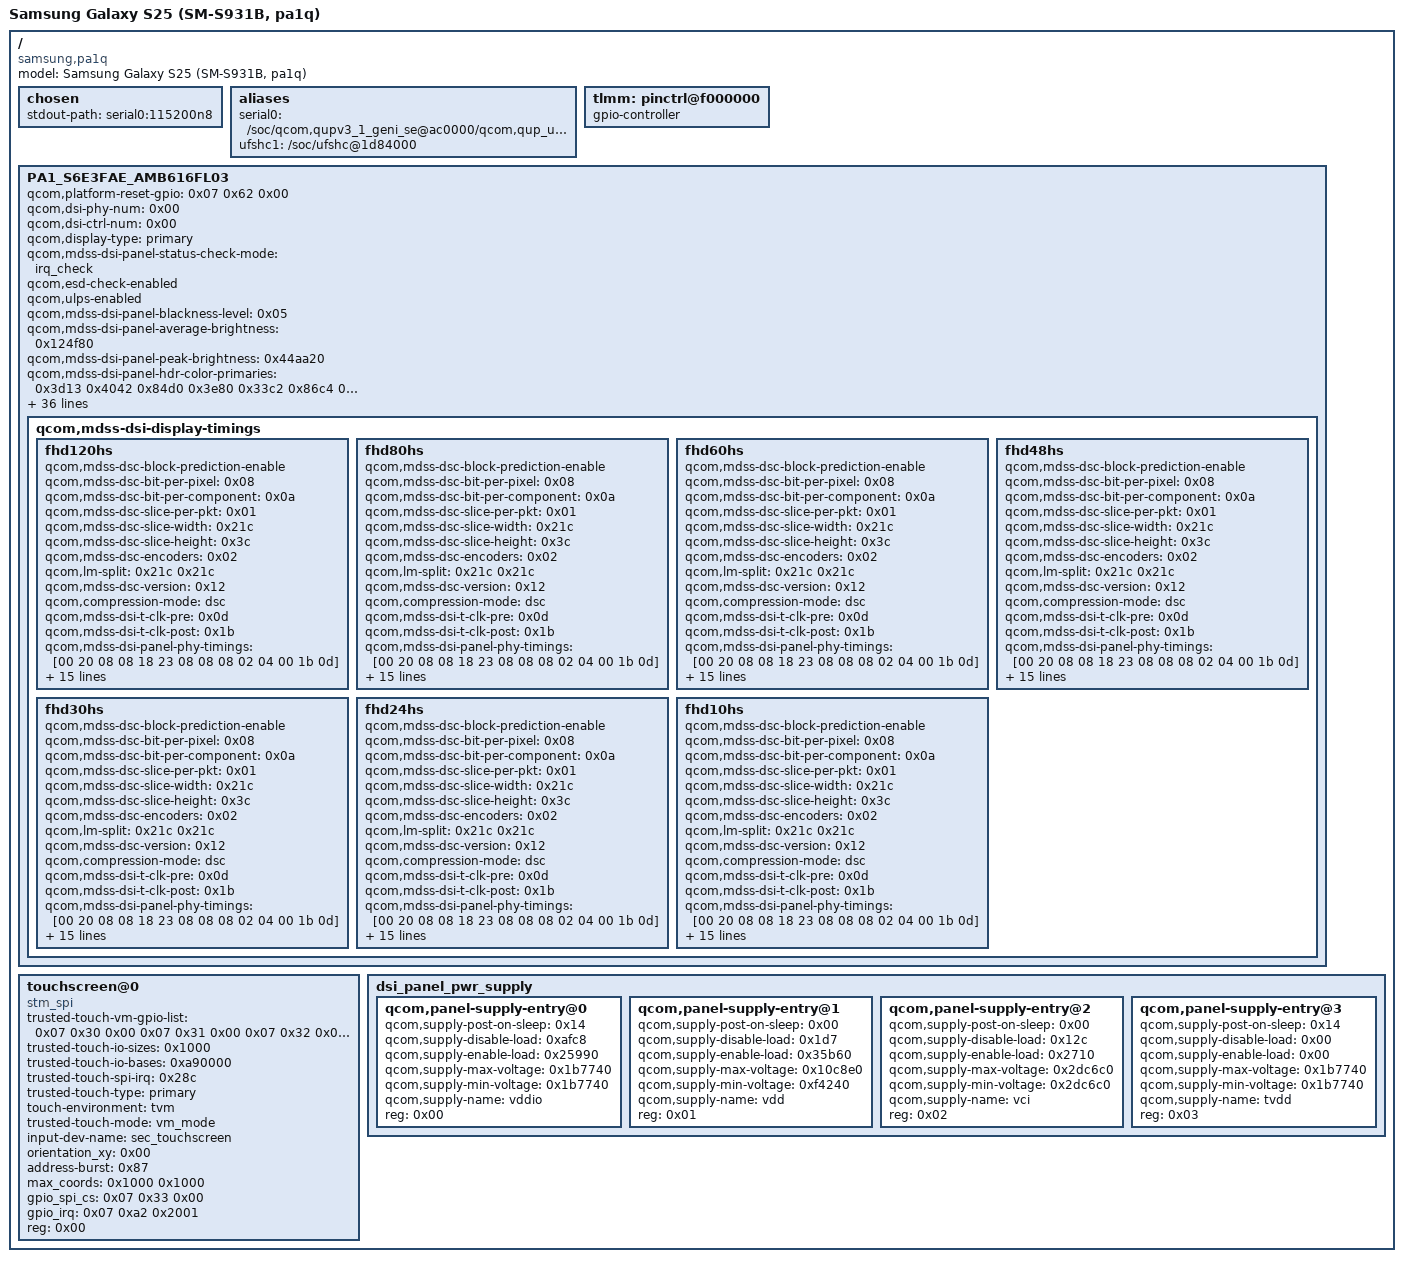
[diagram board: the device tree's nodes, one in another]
/dts-v1/;

/*
 * pa1q (Galaxy S25, SM-S931B) board overlay: the nodes the Sun base tree does not carry.
 *
 * Every value here was extracted from the phone's own firmware, not from the port record:
 * the Sun DTB that ships inside `partitions/vm-bootsys_a` (the graphics VM's tree, which
 * carries the panel, touch and rail nodes for this board). The base SoC tree is `dtb_9`
 * ("Sun SoC", qcom,msn-id 0x26a) of the vendor_boot DTB section. Provenance and the
 * extraction command are in README.md; `check.sh` re-reads the numbers and fails if this
 * file and the firmware disagree.
 *
 * The panel is a Samsung S6E3FAE AMOLED, AMB616FL03, 1080x2340, DSI command mode with DSC,
 * seven refresh rates (120/80/60/48/30/24/10 Hz). Touch is an STMicroelectronics controller
 * on QUPv3 SE4 (spi@a90000). The panel rails are vddio 1.8 V, vdd 1.0-1.1 V, vci 3.0 V,
 * tvdd 1.8 V.
 */

/ {
	model = "Samsung Galaxy S25 (SM-S931B, pa1q)";
	compatible = "samsung,pa1q", "qcom,sun";

	chosen {
		stdout-path = "serial0:115200n8";
	};

	aliases {
		serial0 = "/soc/qcom,qupv3_1_geni_se@ac0000/qcom,qup_uart@a9c000";
		ufshc1 = "/soc/ufshc@1d84000";
	};

	/* Placeholder for the TLMM the extracted nodes point at by phandle. The real node is
	 * pinctrl@f000000 in the Sun base tree. */
	tlmm: pinctrl@f000000 {
		phandle = <0x07>;
		#gpio-cells = <0x02>;
		gpio-controller;
	};

	/* ---------------------------------------------------------------- panel */

			PA1_S6E3FAE_AMB616FL03: PA1_S6E3FAE_AMB616FL03 {
				phandle = <0x53>;
				qcom,platform-reset-gpio = <0x07 0x62 0x00>;
				qcom,dsi-phy-num = <0x00>;
				qcom,dsi-ctrl-num = <0x00>;
				qcom,display-type = "primary";
				qcom,mdss-dsi-panel-status-check-mode = "irq_check";
				qcom,esd-check-enabled;
				qcom,ulps-enabled;
				qcom,mdss-dsi-panel-blackness-level = <0x05>;
				qcom,mdss-dsi-panel-average-brightness = <0x124f80>;
				qcom,mdss-dsi-panel-peak-brightness = <0x44aa20>;
				qcom,mdss-dsi-panel-hdr-color-primaries = <0x3d13 0x4042 0x84d0 0x3e80 0x33c2 0x86c4 0x1d4c 0xbb8>;
				qcom,mdss-dsi-panel-hdr-enabled;
				qcom,mdss-dsi-tx-eot-append;
				qcom,mdss-dsi-rx-eot-ignore;
				qcom,mdss-dsi-panel-mode-gpio-state = "invalid";
				qcom,mdss-pan-physical-height-dimension = <0x8e>;
				qcom,mdss-pan-physical-width-dimension = <0x42>;
				qcom,mdss-dsi-dma-trigger = "trigger_sw";
				qcom,mdss-dsi-mdp-trigger = "none";
				qcom,mdss-dsi-t-clk-pre = <0x19>;
				qcom,mdss-dsi-t-clk-post = <0x18>;
				qcom,mdss-dsi-lane-3-state;
				qcom,mdss-dsi-lane-2-state;
				qcom,mdss-dsi-lane-1-state;
				qcom,mdss-dsi-lane-0-state;
				qcom,mdss-dsi-color-order = "rgb_swap_rgb";
				qcom,mdss-dsi-virtual-channel-id = <0x00>;
				qcom,mdss-dsi-pixel-packing = "loose";
				qcom,mdss-dsi-wr-mem-continue = <0x3c>;
				qcom,mdss-dsi-wr-mem-start = <0x2c>;
				qcom,mdss-dsi-te-dcs-command = <0x01>;
				qcom,dynamic-mode-switch-type = "dynamic-resolution-switch-immediate";
				qcom,dynamic-mode-switch-enabled;
				qcom,mdss-dsi-te-pin-select = <0x01>;
				qcom,mdss-dsi-panel-type = "dsi_cmd_mode";
				qcom,mdss-dsi-interleave-mode = <0x00>;
				qcom,mdss-brightness-default-level = <0x9f6>;
				qcom,mdss-dsi-bl-min-level = <0x01>;
				qcom,mdss-dsi-bl-pmic-control-type = "bl_ctrl_dcs";
				qcom,mdss-dsi-border-color = <0x00>;
				qcom,mdss-dsi-underflow-color = <0xff>;
				qcom,mdss-dsi-bpp = <0x1e>;
				label = "PA1_S6E3FAE_AMB616FL03";
				qcom,mdss-dsi-panel-name = "PA1_S6E3FAE_AMB616FL03";

				qcom,mdss-dsi-display-timings {

					fhd120hs {
						qcom,mdss-dsc-block-prediction-enable;
						qcom,mdss-dsc-bit-per-pixel = <0x08>;
						qcom,mdss-dsc-bit-per-component = <0x0a>;
						qcom,mdss-dsc-slice-per-pkt = <0x01>;
						qcom,mdss-dsc-slice-width = <0x21c>;
						qcom,mdss-dsc-slice-height = <0x3c>;
						qcom,mdss-dsc-encoders = <0x02>;
						qcom,lm-split = <0x21c 0x21c>;
						qcom,mdss-dsc-version = <0x12>;
						qcom,compression-mode = "dsc";
						qcom,mdss-dsi-t-clk-pre = <0x0d>;
						qcom,mdss-dsi-t-clk-post = <0x1b>;
						qcom,mdss-dsi-panel-phy-timings = [00 20 08 08 18 23 08 08 08 02 04 00 1b 0d];
						qcom,mdss-dsi-panel-clockrate = <0x38af1bc0>;
						qcom,mdss-mdp-transfer-time-us = <0x1d6d>;
						qcom,mdss-dsi-panel-framerate = <0x78>;
						samsung,mdss-dsi-sot-hs-mode;
						qcom,mdss-dsi-v-front-porch = <0x0c>;
						qcom,mdss-dsi-v-back-porch = <0x1c>;
						qcom,mdss-dsi-v-pulse-width = <0x1c>;
						qcom,mdss-dsi-h-sync-skew = <0x00>;
						qcom,mdss-dsi-h-front-porch = <0x1c>;
						qcom,mdss-dsi-h-back-porch = <0x1c>;
						qcom,mdss-dsi-h-pulse-width = <0x1c>;
						qcom,mdss-dsi-panel-height = <0x924>;
						qcom,mdss-dsi-panel-width = <0x438>;
						qcom,default-topology-index = <0x00>;
						qcom,display-topology = <0x02 0x02 0x01>;
					};

					fhd80hs {
						qcom,mdss-dsc-block-prediction-enable;
						qcom,mdss-dsc-bit-per-pixel = <0x08>;
						qcom,mdss-dsc-bit-per-component = <0x0a>;
						qcom,mdss-dsc-slice-per-pkt = <0x01>;
						qcom,mdss-dsc-slice-width = <0x21c>;
						qcom,mdss-dsc-slice-height = <0x3c>;
						qcom,mdss-dsc-encoders = <0x02>;
						qcom,lm-split = <0x21c 0x21c>;
						qcom,mdss-dsc-version = <0x12>;
						qcom,compression-mode = "dsc";
						qcom,mdss-dsi-t-clk-pre = <0x0d>;
						qcom,mdss-dsi-t-clk-post = <0x1b>;
						qcom,mdss-dsi-panel-phy-timings = [00 20 08 08 18 23 08 08 08 02 04 00 1b 0d];
						qcom,mdss-dsi-panel-clockrate = <0x38af1bc0>;
						qcom,mdss-mdp-transfer-time-us = <0x1d6d>;
						qcom,mdss-dsi-panel-framerate = <0x50>;
						samsung,mdss-dsi-sot-hs-mode;
						qcom,mdss-dsi-v-front-porch = <0x0d>;
						qcom,mdss-dsi-v-back-porch = <0x1c>;
						qcom,mdss-dsi-v-pulse-width = <0x1c>;
						qcom,mdss-dsi-h-sync-skew = <0x00>;
						qcom,mdss-dsi-h-front-porch = <0x1c>;
						qcom,mdss-dsi-h-back-porch = <0x1c>;
						qcom,mdss-dsi-h-pulse-width = <0x1c>;
						qcom,mdss-dsi-panel-height = <0x924>;
						qcom,mdss-dsi-panel-width = <0x438>;
						qcom,default-topology-index = <0x00>;
						qcom,display-topology = <0x02 0x02 0x01>;
					};

					fhd60hs {
						qcom,mdss-dsc-block-prediction-enable;
						qcom,mdss-dsc-bit-per-pixel = <0x08>;
						qcom,mdss-dsc-bit-per-component = <0x0a>;
						qcom,mdss-dsc-slice-per-pkt = <0x01>;
						qcom,mdss-dsc-slice-width = <0x21c>;
						qcom,mdss-dsc-slice-height = <0x3c>;
						qcom,mdss-dsc-encoders = <0x02>;
						qcom,lm-split = <0x21c 0x21c>;
						qcom,mdss-dsc-version = <0x12>;
						qcom,compression-mode = "dsc";
						qcom,mdss-dsi-t-clk-pre = <0x0d>;
						qcom,mdss-dsi-t-clk-post = <0x1b>;
						qcom,mdss-dsi-panel-phy-timings = [00 20 08 08 18 23 08 08 08 02 04 00 1b 0d];
						qcom,mdss-dsi-panel-clockrate = <0x38af1bc0>;
						qcom,mdss-mdp-transfer-time-us = <0x1d6d>;
						qcom,mdss-dsi-panel-framerate = <0x3c>;
						samsung,mdss-dsi-sot-hs-mode;
						qcom,mdss-dsi-v-front-porch = <0x0e>;
						qcom,mdss-dsi-v-back-porch = <0x1c>;
						qcom,mdss-dsi-v-pulse-width = <0x1c>;
						qcom,mdss-dsi-h-sync-skew = <0x00>;
						qcom,mdss-dsi-h-front-porch = <0x1c>;
						qcom,mdss-dsi-h-back-porch = <0x1c>;
						qcom,mdss-dsi-h-pulse-width = <0x1c>;
						qcom,mdss-dsi-panel-height = <0x924>;
						qcom,mdss-dsi-panel-width = <0x438>;
						qcom,default-topology-index = <0x00>;
						qcom,display-topology = <0x02 0x02 0x01>;
					};

					fhd48hs {
						qcom,mdss-dsc-block-prediction-enable;
						qcom,mdss-dsc-bit-per-pixel = <0x08>;
						qcom,mdss-dsc-bit-per-component = <0x0a>;
						qcom,mdss-dsc-slice-per-pkt = <0x01>;
						qcom,mdss-dsc-slice-width = <0x21c>;
						qcom,mdss-dsc-slice-height = <0x3c>;
						qcom,mdss-dsc-encoders = <0x02>;
						qcom,lm-split = <0x21c 0x21c>;
						qcom,mdss-dsc-version = <0x12>;
						qcom,compression-mode = "dsc";
						qcom,mdss-dsi-t-clk-pre = <0x0d>;
						qcom,mdss-dsi-t-clk-post = <0x1b>;
						qcom,mdss-dsi-panel-phy-timings = [00 20 08 08 18 23 08 08 08 02 04 00 1b 0d];
						qcom,mdss-dsi-panel-clockrate = <0x38af1bc0>;
						qcom,mdss-mdp-transfer-time-us = <0x1d6d>;
						qcom,mdss-dsi-panel-framerate = <0x30>;
						samsung,mdss-dsi-sot-hs-mode;
						qcom,mdss-dsi-v-front-porch = <0x0f>;
						qcom,mdss-dsi-v-back-porch = <0x1c>;
						qcom,mdss-dsi-v-pulse-width = <0x1c>;
						qcom,mdss-dsi-h-sync-skew = <0x00>;
						qcom,mdss-dsi-h-front-porch = <0x1c>;
						qcom,mdss-dsi-h-back-porch = <0x1c>;
						qcom,mdss-dsi-h-pulse-width = <0x1c>;
						qcom,mdss-dsi-panel-height = <0x924>;
						qcom,mdss-dsi-panel-width = <0x438>;
						qcom,default-topology-index = <0x00>;
						qcom,display-topology = <0x02 0x02 0x01>;
					};

					fhd30hs {
						qcom,mdss-dsc-block-prediction-enable;
						qcom,mdss-dsc-bit-per-pixel = <0x08>;
						qcom,mdss-dsc-bit-per-component = <0x0a>;
						qcom,mdss-dsc-slice-per-pkt = <0x01>;
						qcom,mdss-dsc-slice-width = <0x21c>;
						qcom,mdss-dsc-slice-height = <0x3c>;
						qcom,mdss-dsc-encoders = <0x02>;
						qcom,lm-split = <0x21c 0x21c>;
						qcom,mdss-dsc-version = <0x12>;
						qcom,compression-mode = "dsc";
						qcom,mdss-dsi-t-clk-pre = <0x0d>;
						qcom,mdss-dsi-t-clk-post = <0x1b>;
						qcom,mdss-dsi-panel-phy-timings = [00 20 08 08 18 23 08 08 08 02 04 00 1b 0d];
						qcom,mdss-dsi-panel-clockrate = <0x38af1bc0>;
						qcom,mdss-mdp-transfer-time-us = <0x1d6d>;
						qcom,mdss-dsi-panel-framerate = <0x1e>;
						samsung,mdss-dsi-sot-hs-mode;
						qcom,mdss-dsi-v-front-porch = <0x10>;
						qcom,mdss-dsi-v-back-porch = <0x1c>;
						qcom,mdss-dsi-v-pulse-width = <0x1c>;
						qcom,mdss-dsi-h-sync-skew = <0x00>;
						qcom,mdss-dsi-h-front-porch = <0x1c>;
						qcom,mdss-dsi-h-back-porch = <0x1c>;
						qcom,mdss-dsi-h-pulse-width = <0x1c>;
						qcom,mdss-dsi-panel-height = <0x924>;
						qcom,mdss-dsi-panel-width = <0x438>;
						qcom,default-topology-index = <0x00>;
						qcom,display-topology = <0x02 0x02 0x01>;
					};

					fhd24hs {
						qcom,mdss-dsc-block-prediction-enable;
						qcom,mdss-dsc-bit-per-pixel = <0x08>;
						qcom,mdss-dsc-bit-per-component = <0x0a>;
						qcom,mdss-dsc-slice-per-pkt = <0x01>;
						qcom,mdss-dsc-slice-width = <0x21c>;
						qcom,mdss-dsc-slice-height = <0x3c>;
						qcom,mdss-dsc-encoders = <0x02>;
						qcom,lm-split = <0x21c 0x21c>;
						qcom,mdss-dsc-version = <0x12>;
						qcom,compression-mode = "dsc";
						qcom,mdss-dsi-t-clk-pre = <0x0d>;
						qcom,mdss-dsi-t-clk-post = <0x1b>;
						qcom,mdss-dsi-panel-phy-timings = [00 20 08 08 18 23 08 08 08 02 04 00 1b 0d];
						qcom,mdss-dsi-panel-clockrate = <0x38af1bc0>;
						qcom,mdss-mdp-transfer-time-us = <0x1d6d>;
						qcom,mdss-dsi-panel-framerate = <0x18>;
						samsung,mdss-dsi-sot-hs-mode;
						qcom,mdss-dsi-v-front-porch = <0x11>;
						qcom,mdss-dsi-v-back-porch = <0x1c>;
						qcom,mdss-dsi-v-pulse-width = <0x1c>;
						qcom,mdss-dsi-h-sync-skew = <0x00>;
						qcom,mdss-dsi-h-front-porch = <0x1c>;
						qcom,mdss-dsi-h-back-porch = <0x1c>;
						qcom,mdss-dsi-h-pulse-width = <0x1c>;
						qcom,mdss-dsi-panel-height = <0x924>;
						qcom,mdss-dsi-panel-width = <0x438>;
						qcom,default-topology-index = <0x00>;
						qcom,display-topology = <0x02 0x02 0x01>;
					};

					fhd10hs {
						qcom,mdss-dsc-block-prediction-enable;
						qcom,mdss-dsc-bit-per-pixel = <0x08>;
						qcom,mdss-dsc-bit-per-component = <0x0a>;
						qcom,mdss-dsc-slice-per-pkt = <0x01>;
						qcom,mdss-dsc-slice-width = <0x21c>;
						qcom,mdss-dsc-slice-height = <0x3c>;
						qcom,mdss-dsc-encoders = <0x02>;
						qcom,lm-split = <0x21c 0x21c>;
						qcom,mdss-dsc-version = <0x12>;
						qcom,compression-mode = "dsc";
						qcom,mdss-dsi-t-clk-pre = <0x0d>;
						qcom,mdss-dsi-t-clk-post = <0x1b>;
						qcom,mdss-dsi-panel-phy-timings = [00 20 08 08 18 23 08 08 08 02 04 00 1b 0d];
						qcom,mdss-dsi-panel-clockrate = <0x38af1bc0>;
						qcom,mdss-mdp-transfer-time-us = <0x1d6d>;
						qcom,mdss-dsi-panel-framerate = <0x0a>;
						samsung,mdss-dsi-sot-hs-mode;
						qcom,mdss-dsi-v-front-porch = <0x12>;
						qcom,mdss-dsi-v-back-porch = <0x1c>;
						qcom,mdss-dsi-v-pulse-width = <0x1c>;
						qcom,mdss-dsi-h-sync-skew = <0x00>;
						qcom,mdss-dsi-h-front-porch = <0x1c>;
						qcom,mdss-dsi-h-back-porch = <0x1c>;
						qcom,mdss-dsi-h-pulse-width = <0x1c>;
						qcom,mdss-dsi-panel-height = <0x924>;
						qcom,mdss-dsi-panel-width = <0x438>;
						qcom,default-topology-index = <0x00>;
						qcom,display-topology = <0x02 0x02 0x01>;
					};
				};
			};


	/* ----------------------------------------------------------------- touch */

				touchscreen@0 {
					trusted-touch-vm-gpio-list = <0x07 0x30 0x00 0x07 0x31 0x00 0x07 0x32 0x00 0x07 0x33 0x00 0x07 0xa2 0x2008>;
					trusted-touch-io-sizes = <0x1000>;
					trusted-touch-io-bases = <0xa90000>;
					trusted-touch-spi-irq = <0x28c>;
					trusted-touch-type = "primary";
					touch-environment = "tvm";
					trusted-touch-mode = "vm_mode";
					input-dev-name = "sec_touchscreen";
					orientation_xy = <0x00>;
					address-burst = <0x87>;
					max_coords = <0x1000 0x1000>;
					gpio_spi_cs = <0x07 0x33 0x00>;
					gpio_irq = <0x07 0xa2 0x2001>;
					reg = <0x00>;
					compatible = "stm_spi";
					status = "ok";
				};

	/* ----------------------------------------------------------------- rails */

		dsi_panel_pwr_supply: dsi_panel_pwr_supply {
			phandle = <0x59>;
			#size-cells = <0x00>;
			#address-cells = <0x01>;

			qcom,panel-supply-entry@0 {
				qcom,supply-post-on-sleep = <0x14>;
				qcom,supply-disable-load = <0xafc8>;
				qcom,supply-enable-load = <0x25990>;
				qcom,supply-max-voltage = <0x1b7740>;
				qcom,supply-min-voltage = <0x1b7740>;
				qcom,supply-name = "vddio";
				reg = <0x00>;
			};

			qcom,panel-supply-entry@1 {
				qcom,supply-post-on-sleep = <0x00>;
				qcom,supply-disable-load = <0x1d7>;
				qcom,supply-enable-load = <0x35b60>;
				qcom,supply-max-voltage = <0x10c8e0>;
				qcom,supply-min-voltage = <0xf4240>;
				qcom,supply-name = "vdd";
				reg = <0x01>;
			};

			qcom,panel-supply-entry@2 {
				qcom,supply-post-on-sleep = <0x00>;
				qcom,supply-disable-load = <0x12c>;
				qcom,supply-enable-load = <0x2710>;
				qcom,supply-max-voltage = <0x2dc6c0>;
				qcom,supply-min-voltage = <0x2dc6c0>;
				qcom,supply-name = "vci";
				reg = <0x02>;
			};

			qcom,panel-supply-entry@3 {
				qcom,supply-post-on-sleep = <0x14>;
				qcom,supply-disable-load = <0x00>;
				qcom,supply-enable-load = <0x00>;
				qcom,supply-max-voltage = <0x1b7740>;
				qcom,supply-min-voltage = <0x1b7740>;
				qcom,supply-name = "tvdd";
				reg = <0x03>;
			};
		};
};
